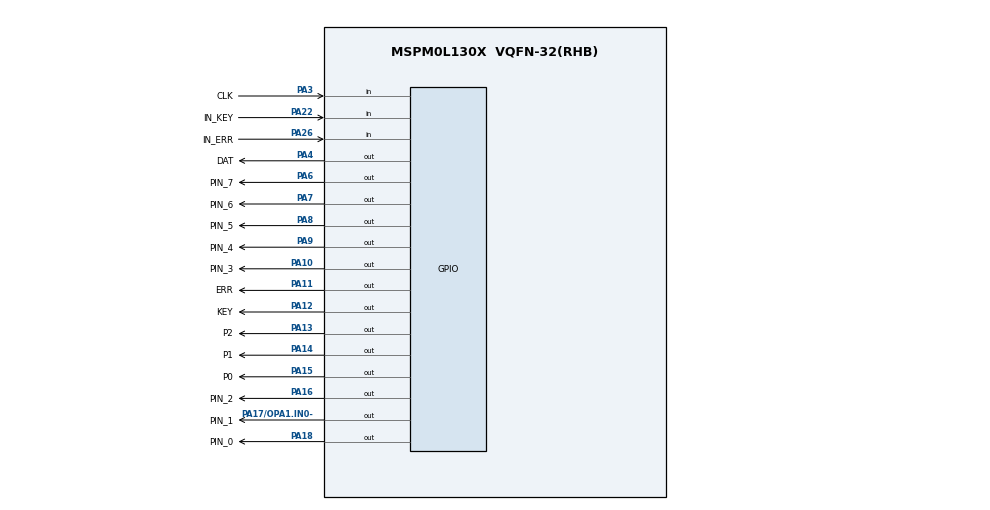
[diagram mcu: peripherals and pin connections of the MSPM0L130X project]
/**
 * @cliArgs --device "MSPM0L130X" --package "VQFN-32(RHB)" --part "Default" --product "mspm0_sdk@1.30.00.03"
 * @versions {"tool":"1.19.0+3426"}
 */

/**
 * Import the modules used in this configuration.
 */
const ADC12   = scripting.addModule("/ti/driverlib/ADC12", {}, false);
const ADC121  = ADC12.addInstance();
const GPIO    = scripting.addModule("/ti/driverlib/GPIO", {}, false);
const GPIO1   = GPIO.addInstance();
const GPIO2   = GPIO.addInstance();
const GPIO3   = GPIO.addInstance();
const GPIO4   = GPIO.addInstance();
const SYSCTL  = scripting.addModule("/ti/driverlib/SYSCTL");
const SYSTICK = scripting.addModule("/ti/driverlib/SYSTICK");
const TIMER   = scripting.addModule("/ti/driverlib/TIMER", {}, false);
const TIMER1  = TIMER.addInstance();

/**
 * Write custom configuration values to the imported modules.
 */
const gate7  = system.clockTree["MFPCLKGATE"];
gate7.enable = true;

ADC121.$name                             = "ADC_VOLTAGE";
ADC121.repeatMode                        = true;
ADC121.adcMem0_name                      = "ADC_CH0";
ADC121.interruptPriority                 = "0";
ADC121.sampClkSrc                        = "DL_ADC12_CLOCK_ULPCLK";
ADC121.sampleTime0                       = "2us";
ADC121.sampClkDiv                        = "DL_ADC12_CLOCK_DIVIDE_8";
ADC121.configureDMA                      = true;
ADC121.enabledDMATriggers                = ["DL_ADC12_DMA_MEM0_RESULT_LOADED"];
ADC121.sampCnt                           = 1;
ADC121.adcPin0Config.$name               = "ti_driverlib_gpio_GPIOPinGeneric0";
ADC121.adcPin0Config.hideOutputInversion = scripting.forceWrite(false);
ADC121.DMA_CHANNEL.$name                 = "DMA_CH0";
ADC121.DMA_CHANNEL.addressMode           = "f2b";
ADC121.DMA_CHANNEL.srcLength             = "HALF_WORD";
ADC121.DMA_CHANNEL.dstLength             = "HALF_WORD";
ADC121.DMA_CHANNEL.configureTransferSize = true;
ADC121.DMA_CHANNEL.transferMode          = "FULL_CH_REPEAT_SINGLE";
ADC121.DMA_CHANNEL.transferSize          = 40;

const Board = scripting.addModule("/ti/driverlib/Board", {}, false);

GPIO1.$name                         = "LED";
GPIO1.associatedPins.create(10);
GPIO1.associatedPins[0].$name       = "PIN_0";
GPIO1.associatedPins[0].pin.$assign = "PA18";
GPIO1.associatedPins[1].$name       = "PIN_1";
GPIO1.associatedPins[1].pin.$assign = "PA17/OPA1.IN0-";
GPIO1.associatedPins[2].$name       = "PIN_2";
GPIO1.associatedPins[2].pin.$assign = "PA16";
GPIO1.associatedPins[3].$name       = "PIN_3";
GPIO1.associatedPins[3].pin.$assign = "PA10";
GPIO1.associatedPins[4].$name       = "PIN_4";
GPIO1.associatedPins[4].pin.$assign = "PA9";
GPIO1.associatedPins[5].$name       = "PIN_5";
GPIO1.associatedPins[5].pin.$assign = "PA8";
GPIO1.associatedPins[6].$name       = "PIN_6";
GPIO1.associatedPins[6].pin.$assign = "PA7";
GPIO1.associatedPins[7].$name       = "PIN_7";
GPIO1.associatedPins[7].pin.$assign = "PA6";
GPIO1.associatedPins[8].$name       = "ERR";
GPIO1.associatedPins[8].pin.$assign = "PA11";
GPIO1.associatedPins[9].$name       = "KEY";
GPIO1.associatedPins[9].pin.$assign = "PA12";

GPIO2.$name                                 = "GRAY_IN";
GPIO2.associatedPins.create(2);
GPIO2.associatedPins[0].$name               = "IN_KEY";
GPIO2.associatedPins[0].direction           = "INPUT";
GPIO2.associatedPins[0].internalResistor    = "PULL_UP";
GPIO2.associatedPins[0].interruptEn         = true;
GPIO2.associatedPins[0].polarity            = "FALL";
GPIO2.associatedPins[0].assignedPortSegment = "Upper";
GPIO2.associatedPins[0].pin.$assign         = "PA22";
GPIO2.associatedPins[1].$name               = "IN_ERR";
GPIO2.associatedPins[1].direction           = "INPUT";
GPIO2.associatedPins[1].pin.$assign         = "PA26";

GPIO3.$name                         = "Gray_Address";
GPIO3.associatedPins.create(3);
GPIO3.associatedPins[0].$name       = "P0";
GPIO3.associatedPins[0].pin.$assign = "PA15";
GPIO3.associatedPins[1].$name       = "P1";
GPIO3.associatedPins[1].pin.$assign = "PA14";
GPIO3.associatedPins[2].$name       = "P2";
GPIO3.associatedPins[2].pin.$assign = "PA13";

GPIO4.$name                               = "Serial";
GPIO4.associatedPins.create(2);
GPIO4.associatedPins[0].$name             = "CLK";
GPIO4.associatedPins[0].direction         = "INPUT";
GPIO4.associatedPins[0].interruptEn       = true;
GPIO4.associatedPins[0].interruptPriority = "0";
GPIO4.associatedPins[0].polarity          = "RISE";
GPIO4.associatedPins[0].pin.$assign       = "PA3";
GPIO4.associatedPins[1].$name             = "DAT";
GPIO4.associatedPins[1].interruptEn       = true;
GPIO4.associatedPins[1].polarity          = "RISE_FALL";
GPIO4.associatedPins[1].interruptPriority = "0";
GPIO4.associatedPins[1].ioStructure       = "SD";
GPIO4.associatedPins[1].pin.$assign       = "PA4";

SYSCTL.MFCLKEn     = true;
SYSCTL.clockTreeEn = true;

SYSTICK.periodEnable      = true;
SYSTICK.interruptEnable   = true;
SYSTICK.systickEnable     = true;
SYSTICK.period            = 32000;
SYSTICK.interruptPriority = "1";

TIMER1.$name       = "TIMER_0";
TIMER1.timerPeriod = "1 ms";
TIMER1.timerMode   = "PERIODIC_UP";
TIMER1.interrupts  = ["LOAD"];

/**
 * Pinmux solution for unlocked pins/peripherals. This ensures that minor changes to the automatic solver in a future
 * version of the tool will not impact the pinmux you originally saw.  These lines can be completely deleted in order to
 * re-solve from scratch.
 */
ADC121.peripheral.$suggestSolution             = "ADC0";
ADC121.peripheral.adcPin0.$suggestSolution     = "PA27";
ADC121.DMA_CHANNEL.peripheral.$suggestSolution = "DMA_CH0";
Board.peripheral.$suggestSolution              = "DEBUGSS";
Board.peripheral.swclkPin.$suggestSolution     = "PA20";
Board.peripheral.swdioPin.$suggestSolution     = "PA19";
TIMER1.peripheral.$suggestSolution             = "TIMG0";
